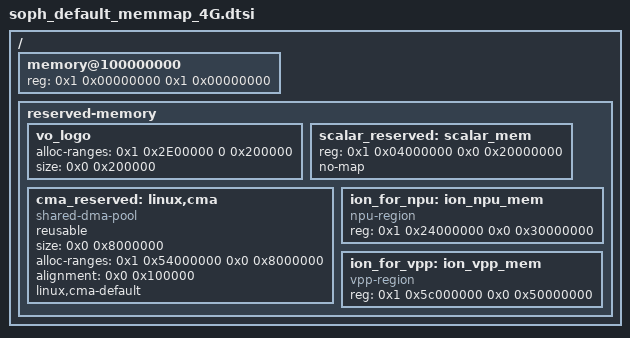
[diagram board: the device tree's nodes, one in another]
/ {
	memory@100000000 {
		device_type = "memory";
		reg = <0x1 0x00000000 0x1 0x00000000>;	//4G
	};

	reserved-memory {
		#address-cells = <0x2>;
		#size-cells = <0x2>;
		ranges;
#ifndef __UBOOT__
		//0x1_02E0_0000 - 0x1_0300_0000 for vo logo (owner: yu.yang@sophgo.com)
		vo_logo: vo_logo {
			alloc-ranges = <0x1 0x2E00000 0 0x200000>; // 2M, for vo logo
			size = <0x0 0x200000>;
		};

		//0x1_0400_0000 - 0x1_2400_0000 for TPU (owner: zhuolin.li@sophgo.com)
		scalar_reserved: scalar_mem {
			reg = <0x1 0x04000000 0x0 0x20000000>;	//512MB for TPU firmware
			no-map;
		};

		//0x1_5400_0000 - 0x1_5c00_0000 for HDMI (owner: yu.yang@sophgo.com)
		cma_reserved: linux,cma {
			compatible = "shared-dma-pool";
			reusable;
			size = <0x0 0x8000000>; // 128m for drm
			alloc-ranges = <0x1 0x54000000 0x0 0x8000000>;   // to fix hdmi audio bug
			alignment = <0x0 0x100000>; // 1MB
			linux,cma-default;
		};

		//0x1_2c00_0000 - 0x1_5c00_0000 for TPU (owner: zhuolin.li@sophgo.com)
		ion_for_npu: ion_npu_mem {
			compatible = "npu-region";
			reg = <0x1 0x24000000 0x0 0x30000000>; // 768MB, for TPU
		};

		//0x1_5c00_0000 - 0x1_C000_0000 for VPP (owner: zhuolin.li@sophgo.com)
		ion_for_vpp: ion_vpp_mem {
			compatible = "vpp-region";
			reg = <0x1 0x5c000000 0x0 0x50000000>; // 1280MB, for VPP
		};
#endif
	};
};
